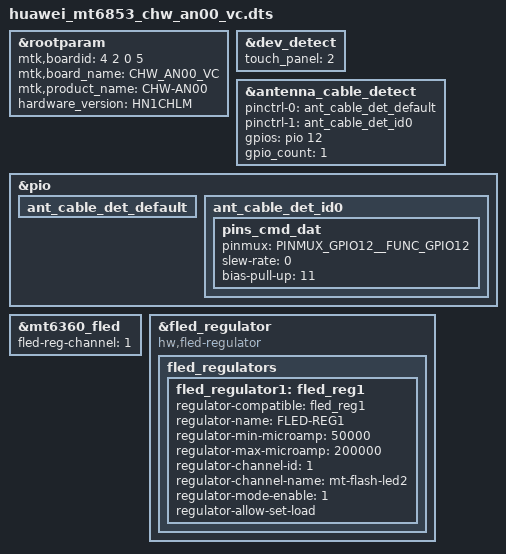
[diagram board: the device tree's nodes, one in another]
#include <dt-bindings/interrupt-controller/irq.h>
#include <dt-bindings/interrupt-controller/arm-gic.h>
#include <dt-bindings/pinctrl/mt6853-pinfunc.h>
/dts-v1/;
/plugin/;

#include "huawei_mt6853_chw_an00_vc/huawei.dtsi"

&rootparam {
    mtk,boardid = <4 2 0 5>;
    mtk,board_name = "CHW_AN00_VC";
    mtk,product_name = "CHW-AN00";
    hardware_version = "HN1CHLM";
};

&dev_detect {
    touch_panel = <2>;
    status = "ok";
};

&antenna_cable_detect {
    pinctrl-names = "default", "id0";
    pinctrl-0 = <&ant_cable_det_default>;
    pinctrl-1 = <&ant_cable_det_id0>;
    gpios = <&pio 12 0 >;
    gpio_count = <1>;
};

&pio {
    ant_cable_det_default: ant_cable_det_default {
    };

    ant_cable_det_id0: ant_cable_det_id0 {
        pins_cmd_dat {
        pinmux = <PINMUX_GPIO12__FUNC_GPIO12>;
        slew-rate = <0>;
        bias-pull-up = <11>;
        };
    };
};

&mt6360_fled {
	fled-reg-channel = <1>;
};

&fled_regulator {
	compatible = "hw,fled-regulator";
	status = "okay";
	fled_regulators {
		fled_regulator1: fled_reg1 {
			regulator-compatible = "fled_reg1";
			regulator-name = "FLED-REG1";
			regulator-min-microamp = <50000>;
			regulator-max-microamp = <200000>;
			regulator-channel-id = <1>;
			regulator-channel-name = "mt-flash-led2";
			regulator-mode-enable = <1>;
			regulator-allow-set-load;
		};
	};
};

#include <k6853v1_64/cust.dtsi>

/*End of this file, DO NOT ADD ANYTHING HERE*/
